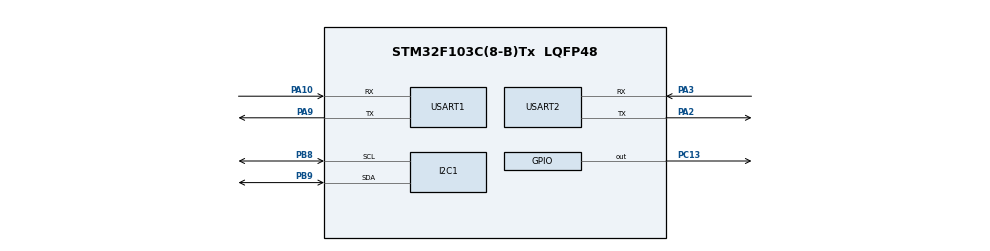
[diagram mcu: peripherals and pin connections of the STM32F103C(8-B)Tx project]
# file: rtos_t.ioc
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Dma.Request0=USART1_RX
Dma.USART1_RX.0.Direction=DMA_PERIPH_TO_MEMORY
Dma.USART1_RX.0.Instance=DMA1_Channel5
Dma.USART1_RX.0.MemDataAlignment=DMA_MDATAALIGN_BYTE
Dma.USART1_RX.0.MemInc=DMA_MINC_ENABLE
Dma.USART1_RX.0.Mode=DMA_NORMAL
Dma.USART1_RX.0.PeriphDataAlignment=DMA_PDATAALIGN_BYTE
Dma.USART1_RX.0.PeriphInc=DMA_PINC_DISABLE
Dma.USART1_RX.0.Priority=DMA_PRIORITY_HIGH
FREERTOS.HEAP_NUMBER=1
FREERTOS.MEMORY_ALLOCATION=0
FREERTOS.Tasks01=defaultTask,0,128,StartDefaultTask,Default,NULL,Dynamic,NULL,NULL;myTask02,-3,128,StartTask02,Default,NULL,Dynamic,NULL,NULL;myTask03,-3,128,StartTask03,Default,NULL,Dynamic,NULL,NULL
FREERTOS.configTOTAL_HEAP_SIZE=4096
Mcu.Family=STM32F1
Mcu.Name=STM32F103C(8-B)Tx
Mcu.Package=LQFP48
NVIC.DMA1_Channel5_IRQn=true\:5\:0\:false\:false\:true\:true\:false\:true
NVIC.PriorityGroup=NVIC_PRIORITYGROUP_4
NVIC.TIM1_UP_IRQn=true\:5\:0\:false\:false\:true\:true\:true\:true
NVIC.TIM2_IRQn=true\:0\:0\:false\:false\:true\:false\:false\:true
NVIC.TimeBase=TIM2_IRQn
NVIC.TimeBaseIP=TIM2
NVIC.USART2_IRQn=true\:5\:0\:false\:false\:true\:true\:true\:true
PA10.Mode=Asynchronous
PA10.Signal=USART1_RX
PA13.Mode=Serial_Wire
PA13.Signal=SYS_JTMS-SWDIO
PA14.Mode=Serial_Wire
PA14.Signal=SYS_JTCK-SWCLK
PA2.Mode=Asynchronous
PA2.Signal=USART2_TX
PA3.Mode=Asynchronous
PA3.Signal=USART2_RX
PA9.Mode=Asynchronous
PA9.Signal=USART1_TX
PB8.Mode=I2C
PB8.Signal=I2C1_SCL
PB9.Mode=I2C
PB9.Signal=I2C1_SDA
PC13-TAMPER-RTC.Signal=GPIO_Output
ProjectManager.HeapSize=0x200
ProjectManager.StackSize=0x400
ProjectManager.TargetToolchain=STM32CubeIDE
RCC.APB1Freq_Value=8000000
RCC.APB2Freq_Value=8000000
TIM1.Period=1000
TIM1.Prescaler=7199
USART1.VirtualMode=VM_ASYNC
USART2.VirtualMode=VM_ASYNC
VP_FREERTOS_VS_CMSIS_V1.Mode=CMSIS_V1
VP_SYS_VS_tim2.Mode=TIM2
VP_TIM1_VS_ClockSourceINT.Mode=Internal
board=custom

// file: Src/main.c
/* USER CODE BEGIN Header */
/**
  ******************************************************************************
  * @file           : main.c
  * @brief          : Main program body
  ******************************************************************************
  * @attention
  *
  * <h2><center>&copy; Copyright (c) 2019 STMicroelectronics.
  * All rights reserved.</center></h2>
  *
  * This software component is licensed by ST under BSD 3-Clause license,
  * the "License"; You may not use this file except in compliance with the
  * License. You may obtain a copy of the License at:
  *                        opensource.org/licenses/BSD-3-Clause
  *
  ******************************************************************************
  */
/* USER CODE END Header */

#include "main.h"
#include "cmsis_os.h"

I2C_HandleTypeDef hi2c1;

TIM_HandleTypeDef htim1;

UART_HandleTypeDef huart1;
UART_HandleTypeDef huart2;
DMA_HandleTypeDef hdma_usart1_rx;

osThreadId defaultTaskHandle;
osThreadId myTask02Handle;
osThreadId myTask03Handle;

void SystemClock_Config(void);
static void MX_GPIO_Init(void);
static void MX_DMA_Init(void);
static void MX_I2C1_Init(void);
static void MX_TIM1_Init(void);
static void MX_USART1_UART_Init(void);
static void MX_USART2_UART_Init(void);
void StartDefaultTask(void const * argument);
void StartTask02(void const * argument);
void StartTask03(void const * argument);

/* USER CODE BEGIN PFP */
#ifdef __GNUC__
  /* With GCC/RAISONANCE, small printf (option LD Linker->Libraries->Small printf
     set to 'Yes') calls __io_putchar() */
  #define PUTCHAR_PROTOTYPE int __io_putchar(int ch)
#else
  #define PUTCHAR_PROTOTYPE int fputc(int ch, FILE *f)
#endif /* __GNUC__ */
PUTCHAR_PROTOTYPE
{
    /* Place your implementation of fputc here */
    /* e.g. write a character to the USART */

    return ch;
}
/* USER CODE END PFP */

/* USER CODE BEGIN 0 */
char Rx_indx,Rx_indx1, Rx_data[2], Rx_Buffer[100],temp[50], Transfer_cplt;
char * pch ;
char ch[7]="Task 1\n";
/* USER CODE END 0 */

int main(void)
{

  /* MCU Configuration--------------------------------------------------------*/

  /* Reset of all peripherals, Initializes the Flash interface and the Systick. */
  HAL_Init();

  /* Configure the system clock */
  SystemClock_Config();

  /* Initialize all configured peripherals */
  MX_GPIO_Init();
  MX_DMA_Init();
  MX_I2C1_Init();
  MX_TIM1_Init();
  MX_USART1_UART_Init();
  MX_USART2_UART_Init();
  /* USER CODE BEGIN 2 */
//  HAL_UART_Receive_IT(&huart1, (uint8_t *) Rx_data, 1);
  /* USER CODE END 2 */

  /* Create the thread(s) */
  /* definition and creation of defaultTask */
  osThreadDef(defaultTask, StartDefaultTask, osPriorityNormal, 0, 128);
  defaultTaskHandle = osThreadCreate(osThread(defaultTask), NULL);

  /* definition and creation of myTask02 */
  osThreadDef(myTask02, StartTask02, osPriorityIdle, 0, 128);
  myTask02Handle = osThreadCreate(osThread(myTask02), NULL);

  /* definition and creation of myTask03 */
  osThreadDef(myTask03, StartTask03, osPriorityIdle, 0, 128);
  myTask03Handle = osThreadCreate(osThread(myTask03), NULL);

  /* Start scheduler */
  osKernelStart();

  /* We should never get here as control is now taken by the scheduler */

  /* Infinite loop */
  while (1)
  {

  }
}

void SystemClock_Config(void)
{
  RCC_OscInitTypeDef RCC_OscInitStruct = {0};
  RCC_ClkInitTypeDef RCC_ClkInitStruct = {0};

  /** Initializes the CPU, AHB and APB busses clocks
  */
  RCC_OscInitStruct.OscillatorType = RCC_OSCILLATORTYPE_HSI;
  RCC_OscInitStruct.HSIState = RCC_HSI_ON;
  RCC_OscInitStruct.HSICalibrationValue = RCC_HSICALIBRATION_DEFAULT;
  RCC_OscInitStruct.PLL.PLLState = RCC_PLL_NONE;
  if (HAL_RCC_OscConfig(&RCC_OscInitStruct) != HAL_OK)
  {
    Error_Handler();
  }
  /** Initializes the CPU, AHB and APB busses clocks
  */
  RCC_ClkInitStruct.ClockType = RCC_CLOCKTYPE_HCLK|RCC_CLOCKTYPE_SYSCLK
                              |RCC_CLOCKTYPE_PCLK1|RCC_CLOCKTYPE_PCLK2;
  RCC_ClkInitStruct.SYSCLKSource = RCC_SYSCLKSOURCE_HSI;
  RCC_ClkInitStruct.AHBCLKDivider = RCC_SYSCLK_DIV1;
  RCC_ClkInitStruct.APB1CLKDivider = RCC_HCLK_DIV1;
  RCC_ClkInitStruct.APB2CLKDivider = RCC_HCLK_DIV1;

  if (HAL_RCC_ClockConfig(&RCC_ClkInitStruct, FLASH_LATENCY_0) != HAL_OK)
  {
    Error_Handler();
  }
}

static void MX_I2C1_Init(void)
{

  hi2c1.Instance = I2C1;
  hi2c1.Init.ClockSpeed = 100000;
  hi2c1.Init.DutyCycle = I2C_DUTYCYCLE_2;
  hi2c1.Init.OwnAddress1 = 0;
  hi2c1.Init.AddressingMode = I2C_ADDRESSINGMODE_7BIT;
  hi2c1.Init.DualAddressMode = I2C_DUALADDRESS_DISABLE;
  hi2c1.Init.OwnAddress2 = 0;
  hi2c1.Init.GeneralCallMode = I2C_GENERALCALL_DISABLE;
  hi2c1.Init.NoStretchMode = I2C_NOSTRETCH_DISABLE;
  if (HAL_I2C_Init(&hi2c1) != HAL_OK)
  {
    Error_Handler();
  }

}

static void MX_TIM1_Init(void)
{

  TIM_ClockConfigTypeDef sClockSourceConfig = {0};
  TIM_MasterConfigTypeDef sMasterConfig = {0};

  htim1.Instance = TIM1;
  htim1.Init.Prescaler = 7199;
  htim1.Init.CounterMode = TIM_COUNTERMODE_UP;
  htim1.Init.Period = 1000;
  htim1.Init.ClockDivision = TIM_CLOCKDIVISION_DIV1;
  htim1.Init.RepetitionCounter = 0;
  htim1.Init.AutoReloadPreload = TIM_AUTORELOAD_PRELOAD_DISABLE;
  if (HAL_TIM_Base_Init(&htim1) != HAL_OK)
  {
    Error_Handler();
  }
  sClockSourceConfig.ClockSource = TIM_CLOCKSOURCE_INTERNAL;
  if (HAL_TIM_ConfigClockSource(&htim1, &sClockSourceConfig) != HAL_OK)
  {
    Error_Handler();
  }
  sMasterConfig.MasterOutputTrigger = TIM_TRGO_RESET;
  sMasterConfig.MasterSlaveMode = TIM_MASTERSLAVEMODE_DISABLE;
  if (HAL_TIMEx_MasterConfigSynchronization(&htim1, &sMasterConfig) != HAL_OK)
  {
    Error_Handler();
  }

}

static void MX_USART1_UART_Init(void)
{

  huart1.Instance = USART1;
  huart1.Init.BaudRate = 115200;
  huart1.Init.WordLength = UART_WORDLENGTH_8B;
  huart1.Init.StopBits = UART_STOPBITS_1;
  huart1.Init.Parity = UART_PARITY_NONE;
  huart1.Init.Mode = UART_MODE_TX_RX;
  huart1.Init.HwFlowCtl = UART_HWCONTROL_NONE;
  huart1.Init.OverSampling = UART_OVERSAMPLING_16;
  if (HAL_UART_Init(&huart1) != HAL_OK)
  {
    Error_Handler();
  }

}

static void MX_USART2_UART_Init(void)
{

  huart2.Instance = USART2;
  huart2.Init.BaudRate = 115200;
  huart2.Init.WordLength = UART_WORDLENGTH_8B;
  huart2.Init.StopBits = UART_STOPBITS_1;
  huart2.Init.Parity = UART_PARITY_NONE;
  huart2.Init.Mode = UART_MODE_TX_RX;
  huart2.Init.HwFlowCtl = UART_HWCONTROL_NONE;
  huart2.Init.OverSampling = UART_OVERSAMPLING_16;
  if (HAL_UART_Init(&huart2) != HAL_OK)
  {
    Error_Handler();
  }

}

static void MX_DMA_Init(void)
{

  /* DMA controller clock enable */
  __HAL_RCC_DMA1_CLK_ENABLE();

  /* DMA interrupt init */
  /* DMA1_Channel5_IRQn interrupt configuration */
  HAL_NVIC_SetPriority(DMA1_Channel5_IRQn, 5, 0);
  HAL_NVIC_EnableIRQ(DMA1_Channel5_IRQn);

}

static void MX_GPIO_Init(void)
{
  GPIO_InitTypeDef GPIO_InitStruct = {0};

  /* GPIO Ports Clock Enable */
  __HAL_RCC_GPIOC_CLK_ENABLE();
  __HAL_RCC_GPIOA_CLK_ENABLE();
  __HAL_RCC_GPIOB_CLK_ENABLE();

  /*Configure GPIO pin Output Level */
  HAL_GPIO_WritePin(GPIOC, GPIO_PIN_13, GPIO_PIN_RESET);

  /*Configure GPIO pin : PC13 */
  GPIO_InitStruct.Pin = GPIO_PIN_13;
  GPIO_InitStruct.Mode = GPIO_MODE_OUTPUT_PP;
  GPIO_InitStruct.Pull = GPIO_NOPULL;
  GPIO_InitStruct.Speed = GPIO_SPEED_FREQ_LOW;
  HAL_GPIO_Init(GPIOC, &GPIO_InitStruct);

}

void StartDefaultTask(void const * argument)
{

  /* USER CODE BEGIN 5 */
  /* Infinite loop */
  for(;;)
  {
	 //HAL_GPIO_TogglePin(GPIOC,GPIO_PIN_13);
	       osDelay(1);
  }
  /* USER CODE END 5 */
}

void StartTask02(void const * argument)
{
  /* USER CODE BEGIN StartTask02 */
  /* Infinite loop */
  for(;;)
  {

	  process_MPU();
      osDelay(10);
  }
  /* USER CODE END StartTask02 */
}

void StartTask03(void const * argument)
{
  /* USER CODE BEGIN StartTask03 */
  /* Infinite loop */
  for(;;)
  {
//	  char ch[6] ="Task 2\n";
//	  HAL_UART_Transmit_DMA(&huart2, (uint8_t *)&ch, 7);
//      osDelay(100);
	  readMagnet();
	  //HAL_GPIO_TogglePin(GPIOC,GPIO_PIN_13);
	  osDelay(10);
  }
  /* USER CODE END StartTask03 */
}

void HAL_TIM_PeriodElapsedCallback(TIM_HandleTypeDef *htim)
{
  if (htim->Instance == TIM2) {
    HAL_IncTick();
  }
}

void Error_Handler(void)
{
}

/************************ (C) COPYRIGHT STMicroelectronics *****END OF FILE****/
